# apollo5b register map
Vendor: Ambiq Micro; Series: Apollo; File version: 1.0
CPU: CM55 r1p1, little endian, MPU, FPU, double-precision FPU, DSP, I-cache, D-cache, VTOR, ITCM, DTCM, 4 interrupt priority bits, 0 interrupts, 8 SAU regions
Registers are 32-bit, read-write, reset 0x0 unless marked. A register's access mark holds for its fields unless they carry their own. Offsets are from the block's base; [hi:lo] are bit positions; {n}, {i} and the like mark numbered series; 'fields as' and 'values as' point back to an identical list.

## FPIO — Fast PIO access
Base 0x40011000
{0x0+4i} RD{i} (i=0..6) — GPIO Input {i} ({32i+31}-{32i})
  [31:0] RD{i} — GPIO{32i+31}-{32i} Reads pin state - read only. Returns the pad pin state for pins {32i+31}-{32i} if the PINCFG's input enable (INPEN) is active and RDZERO is inactive.
{0x1C+4i} WT{i} (i=0..6) — GPIO Output {i} ({32i+31}-{32i})
  [31:0] WT{i} — GPIO{32i+31}-{32i} Reads or writes pin state. Writes of 1 bits set output pad signal if the GPIO is enabled for output. Reads return status, including sets/clears through the WTS and WTC registers.
{0x38+4i} WTS{i} (i=0..6) — GPIO Output Set {i} ({32i+31}-{32i})
  [31:0] WTS{i} — GPIO{32i+31}-{32i} Sets pin state. Writing a 1 to any bit sets the corresponding bit in the WT register if the GPIO is enabled for output. Writing a value of 0 has no effect on the corresponding bit in the WT register. Status reads should be made via the WT Register.
{0x54+4i} WTC{i} (i=0..6) — GPIO Output Clear {i} ({32i+31}-{32i})
  [31:0] WTC{i} — GPIO{32i+31}-{32i} Clears pin state. Writing a 1 to any bit clears the corresponding bit in the WT register if the GPIO is enabled for output. Writing a value of 0 has no effect on the corresponding bit in the WT register. Status reads should be made via the WT Register.
{0x70+4i} EN{i} (i=0..6) — GPIO Enable {i} ({32i+31}-{32i})
  [31:0] EN{i} — GPIO{32i+31}-{32i} Enables tri-state pin output. Writing a 1 to any bit enables, and writing a 0 to any bit disables, the output for the corresponding GPIO. Reads return output enable/disable status of GPIO.
{0x8C+4i} ENS{i} (i=0..6) — GPIO Enable Set {i} ({32i+31}-{32i})
  [31:0] ENS{i} — GPIO{32i+31}-{32i} Sets pin tri-state output enables. Writing a 1 to any bit sets the corresponding bit in the EN register. Writing a value of 0 has no effect on the corresponding bit in the EN register. Status reads should be made to the EN Register.
{0xA8+4i} ENC{i} (i=0..6) — GPIO Enable Clear {i} ({32i+31}-{32i})
  [31:0] ENC{i} — GPIO{32i+31}-{32i} Clears pin tri-state output enables. Writing a 1 to any bit clears the corresponding bit in the EN register. Writing a value of 0 has no effect on the corresponding bit in the EN register. Status reads should be made to the EN Register.

## OTP — OTP Controller
Base 0x40014800
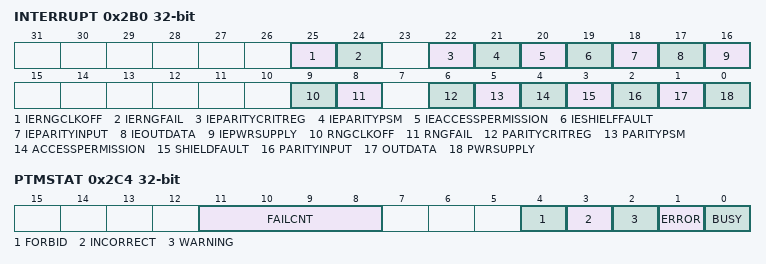
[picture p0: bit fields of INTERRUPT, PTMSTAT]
0x2B0 INTERRUPT — OTP Controller interrupt enable and status.
  [25] IERNGCLKOFF — Enable RNGCLKOFF interrupts.
    0=DISABLE (Disable interrupt.); 1=ENABLE (Enable interrupt.)
  [24] IERNGFAIL — Enable RNGFAIL interrupts.
    0=DISABLE (Disable interrupt.); 1=ENABLE (Enable interrupt.)
  [22] IEPARITYCRITREG — Enable PARITYCRITREG interrupts.
    0=DISABLE (Disable interrupt.); 1=ENABLE (Enable interrupt.)
  [21] IEPARITYPSM — Enable PARITYPSM interrupts.
    0=DISABLE (Disable interrupt.); 1=ENABLE (Enable interrupt.)
  [20] IEACCESSPERMISSION — Enable ACCESSPERMISSION interrupts.
    0=DISABLE (Disable interrupt.); 1=ENABLE (Enable interrupt.)
  [19] IESHIELFFAULT — Enable SHIELDFAULT interrupts.
    0=DISABLE (Disable interrupt.); 1=ENABLE (Enable interrupt.)
  [18] IEPARITYINPUT — Enable PARITYINPUT interrupts.
    0=DISABLE (Disable interrupt.); 1=ENABLE (Enable interrupt.)
  [17] IEOUTDATA — Enable OUTDATA interrupts.
    0=DISABLE (Disable interrupt.); 1=ENABLE (Enable interrupt.)
  [16] IEPWRSUPPLY — Enable PWRSUPPLY interrupts.
    0=DISABLE (Disable interrupt.); 1=ENABLE (Enable interrupt.)
  [9] RNGCLKOFF — RNG internal clock is turned off.
    0=NOINTERR (No interrupt error detected.); 1=INTERR (Interrupt error detected.)
  [8] RNGFAIL — RNG health check failure.
    values as RNGCLKOFF
  [6] PARITYCRITREG — Parity error of critical reg.
    values as RNGCLKOFF
  [5] PARITYPSM — Parity error of the FSM.
    values as RNGCLKOFF
  [4] ACCESSPERMISSION — Access permission error.
    values as RNGCLKOFF
  [3] SHIELDFAULT — Metal shielding fault.
    values as RNGCLKOFF
  [2] PARITYINPUT — Input parity check failure.
    values as RNGCLKOFF
  [1] OUTDATA — Conflict with output data.
    values as RNGCLKOFF
  [0] PWRSUPPLY — Problem with power supply.
    values as RNGCLKOFF
0x2C4 PTMSTAT — OTP Controller Status
  [11:8] FAILCNT — Number of failed OTP cells
  [4] FORBID — PTM locked
    1=LOCKED (PTM is locked); 0=UNLOCKED (PTM is not locked)
  [3] INCORRECT — PTM data is not correctly set
    1=BAD (PTM data is incorrect); 0=GOOD (PTM data good)
  [2] WARNING — PTM is re-run or not initialized
    1=OCCURRED (PTM is re-run or not initialized.); 0=NONE (No PTM warning)
  [1] ERROR — PTM Error.
    0=VALID (No PTM error.); 1=INVALID (PTM error occurred.)
  [0] BUSY — Controller Busy.
    0=IDLE (OTP controller is idle and ready for a new command.); 1=PTMBUSY (OTP controller is busy.)
